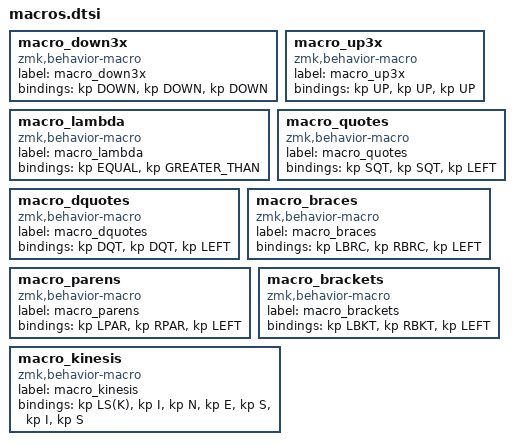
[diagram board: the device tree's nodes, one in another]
macro_down3x: macro_down3x{
compatible = "zmk,behavior-macro";
label = "macro_down3x";
#binding-cells = <0>;
bindings = <&kp DOWN>, <&kp DOWN>, <&kp DOWN>;
};
macro_up3x: macro_up3x{
compatible = "zmk,behavior-macro";
label = "macro_up3x";
#binding-cells = <0>;
bindings = <&kp UP>, <&kp UP>, <&kp UP>;
};
macro_lambda: macro_lambda{
compatible = "zmk,behavior-macro";
label = "macro_lambda";
#binding-cells = <0>;
bindings = <&kp EQUAL>, <&kp GREATER_THAN>;
};
macro_quotes: macro_quotes{
compatible = "zmk,behavior-macro";
label = "macro_quotes";
#binding-cells = <0>;
bindings = <&kp SQT>, <&kp SQT>, <&kp LEFT>;
};
macro_dquotes: macro_dquotes{
compatible = "zmk,behavior-macro";
label = "macro_dquotes";
#binding-cells = <0>;
bindings = <&kp DQT>, <&kp DQT>, <&kp LEFT>;
};
macro_braces: macro_braces{
compatible = "zmk,behavior-macro";
label = "macro_braces";
#binding-cells = <0>;
bindings = <&kp LBRC>, <&kp RBRC>, <&kp LEFT>;
};
macro_parens: macro_parens{
compatible = "zmk,behavior-macro";
label = "macro_parens";
#binding-cells = <0>;
bindings = <&kp LPAR>, <&kp RPAR>, <&kp LEFT>;
};
macro_brackets: macro_brackets{
compatible = "zmk,behavior-macro";
label = "macro_brackets";
#binding-cells = <0>;
bindings = <&kp LBKT>, <&kp RBKT>, <&kp LEFT>;
};
macro_kinesis: macro_kinesis{
compatible = "zmk,behavior-macro";
label = "macro_kinesis";
#binding-cells = <0>;
bindings = <&kp LS(K)>, <&kp I>, <&kp N>, <&kp E>, <&kp S>, <&kp I>, <&kp S>;
};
